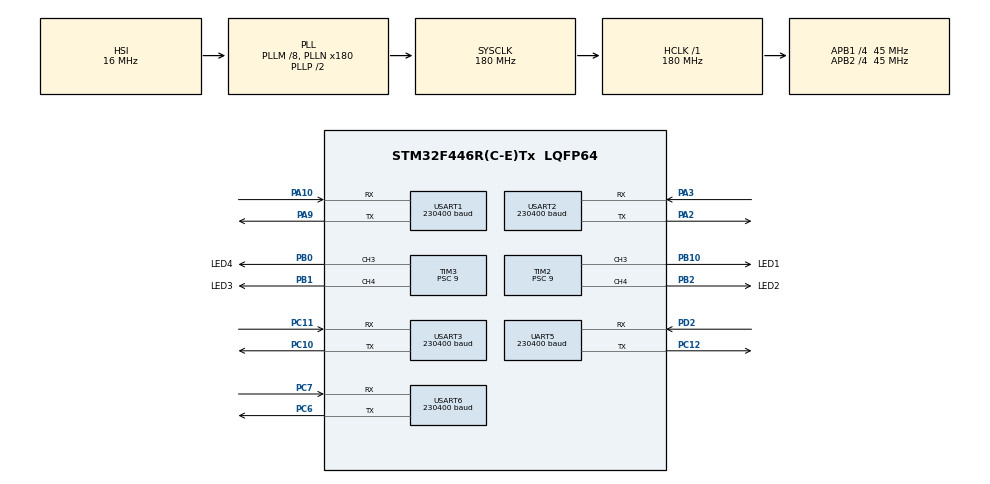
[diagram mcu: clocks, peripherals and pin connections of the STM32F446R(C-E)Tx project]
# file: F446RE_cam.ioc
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Dma.Request0=UART5_RX
Dma.Request1=UART5_TX
Dma.Request2=USART1_RX
Dma.Request3=USART1_TX
Dma.Request4=USART2_RX
Dma.Request5=USART2_TX
Dma.Request6=USART3_RX
Dma.Request7=USART3_TX
Dma.Request8=USART6_RX
Dma.Request9=USART6_TX
Dma.UART5_RX.0.Direction=DMA_PERIPH_TO_MEMORY
Dma.UART5_RX.0.FIFOMode=DMA_FIFOMODE_DISABLE
Dma.UART5_RX.0.Instance=DMA1_Stream0
Dma.UART5_RX.0.MemDataAlignment=DMA_MDATAALIGN_BYTE
Dma.UART5_RX.0.MemInc=DMA_MINC_ENABLE
Dma.UART5_RX.0.Mode=DMA_CIRCULAR
Dma.UART5_RX.0.PeriphDataAlignment=DMA_PDATAALIGN_BYTE
Dma.UART5_RX.0.PeriphInc=DMA_PINC_DISABLE
Dma.UART5_RX.0.Priority=DMA_PRIORITY_LOW
Dma.UART5_TX.1.Direction=DMA_MEMORY_TO_PERIPH
Dma.UART5_TX.1.FIFOMode=DMA_FIFOMODE_DISABLE
Dma.UART5_TX.1.Instance=DMA1_Stream7
Dma.UART5_TX.1.MemDataAlignment=DMA_MDATAALIGN_BYTE
Dma.UART5_TX.1.MemInc=DMA_MINC_ENABLE
Dma.UART5_TX.1.Mode=DMA_CIRCULAR
Dma.UART5_TX.1.PeriphDataAlignment=DMA_PDATAALIGN_BYTE
Dma.UART5_TX.1.PeriphInc=DMA_PINC_DISABLE
Dma.UART5_TX.1.Priority=DMA_PRIORITY_LOW
Dma.USART1_RX.2.Direction=DMA_PERIPH_TO_MEMORY
Dma.USART1_RX.2.FIFOMode=DMA_FIFOMODE_DISABLE
Dma.USART1_RX.2.Instance=DMA2_Stream2
Dma.USART1_RX.2.MemDataAlignment=DMA_MDATAALIGN_BYTE
Dma.USART1_RX.2.MemInc=DMA_MINC_ENABLE
Dma.USART1_RX.2.Mode=DMA_CIRCULAR
Dma.USART1_RX.2.PeriphDataAlignment=DMA_PDATAALIGN_BYTE
Dma.USART1_RX.2.PeriphInc=DMA_PINC_DISABLE
Dma.USART1_RX.2.Priority=DMA_PRIORITY_LOW
Dma.USART1_TX.3.Direction=DMA_MEMORY_TO_PERIPH
Dma.USART1_TX.3.FIFOMode=DMA_FIFOMODE_DISABLE
Dma.USART1_TX.3.Instance=DMA2_Stream7
Dma.USART1_TX.3.MemDataAlignment=DMA_MDATAALIGN_BYTE
Dma.USART1_TX.3.MemInc=DMA_MINC_ENABLE
Dma.USART1_TX.3.Mode=DMA_CIRCULAR
Dma.USART1_TX.3.PeriphDataAlignment=DMA_PDATAALIGN_BYTE
Dma.USART1_TX.3.PeriphInc=DMA_PINC_DISABLE
Dma.USART1_TX.3.Priority=DMA_PRIORITY_LOW
Dma.USART2_RX.4.Direction=DMA_PERIPH_TO_MEMORY
Dma.USART2_RX.4.FIFOMode=DMA_FIFOMODE_DISABLE
Dma.USART2_RX.4.Instance=DMA1_Stream5
Dma.USART2_RX.4.MemDataAlignment=DMA_MDATAALIGN_BYTE
Dma.USART2_RX.4.MemInc=DMA_MINC_ENABLE
Dma.USART2_RX.4.Mode=DMA_CIRCULAR
Dma.USART2_RX.4.PeriphDataAlignment=DMA_PDATAALIGN_BYTE
Dma.USART2_RX.4.PeriphInc=DMA_PINC_DISABLE
Dma.USART2_RX.4.Priority=DMA_PRIORITY_LOW
Dma.USART2_TX.5.Direction=DMA_MEMORY_TO_PERIPH
Dma.USART2_TX.5.FIFOMode=DMA_FIFOMODE_DISABLE
Dma.USART2_TX.5.Instance=DMA1_Stream6
Dma.USART2_TX.5.MemDataAlignment=DMA_MDATAALIGN_BYTE
Dma.USART2_TX.5.MemInc=DMA_MINC_ENABLE
Dma.USART2_TX.5.Mode=DMA_CIRCULAR
Dma.USART2_TX.5.PeriphDataAlignment=DMA_PDATAALIGN_BYTE
Dma.USART2_TX.5.PeriphInc=DMA_PINC_DISABLE
Dma.USART2_TX.5.Priority=DMA_PRIORITY_LOW
Dma.USART3_RX.6.Direction=DMA_PERIPH_TO_MEMORY
Dma.USART3_RX.6.FIFOMode=DMA_FIFOMODE_DISABLE
Dma.USART3_RX.6.Instance=DMA1_Stream1
Dma.USART3_RX.6.MemDataAlignment=DMA_MDATAALIGN_BYTE
Dma.USART3_RX.6.MemInc=DMA_MINC_ENABLE
Dma.USART3_RX.6.Mode=DMA_CIRCULAR
Dma.USART3_RX.6.PeriphDataAlignment=DMA_PDATAALIGN_BYTE
Dma.USART3_RX.6.PeriphInc=DMA_PINC_DISABLE
Dma.USART3_RX.6.Priority=DMA_PRIORITY_LOW
Dma.USART3_TX.7.Direction=DMA_MEMORY_TO_PERIPH
Dma.USART3_TX.7.FIFOMode=DMA_FIFOMODE_DISABLE
Dma.USART3_TX.7.Instance=DMA1_Stream3
Dma.USART3_TX.7.MemDataAlignment=DMA_MDATAALIGN_BYTE
Dma.USART3_TX.7.MemInc=DMA_MINC_ENABLE
Dma.USART3_TX.7.Mode=DMA_CIRCULAR
Dma.USART3_TX.7.PeriphDataAlignment=DMA_PDATAALIGN_BYTE
Dma.USART3_TX.7.PeriphInc=DMA_PINC_DISABLE
Dma.USART3_TX.7.Priority=DMA_PRIORITY_LOW
Dma.USART6_RX.8.Direction=DMA_PERIPH_TO_MEMORY
Dma.USART6_RX.8.FIFOMode=DMA_FIFOMODE_DISABLE
Dma.USART6_RX.8.Instance=DMA2_Stream1
Dma.USART6_RX.8.MemDataAlignment=DMA_MDATAALIGN_BYTE
Dma.USART6_RX.8.MemInc=DMA_MINC_ENABLE
Dma.USART6_RX.8.Mode=DMA_CIRCULAR
Dma.USART6_RX.8.PeriphDataAlignment=DMA_PDATAALIGN_BYTE
Dma.USART6_RX.8.PeriphInc=DMA_PINC_DISABLE
Dma.USART6_RX.8.Priority=DMA_PRIORITY_LOW
Dma.USART6_TX.9.Direction=DMA_MEMORY_TO_PERIPH
Dma.USART6_TX.9.FIFOMode=DMA_FIFOMODE_DISABLE
Dma.USART6_TX.9.Instance=DMA2_Stream6
Dma.USART6_TX.9.MemDataAlignment=DMA_MDATAALIGN_BYTE
Dma.USART6_TX.9.MemInc=DMA_MINC_ENABLE
Dma.USART6_TX.9.Mode=DMA_CIRCULAR
Dma.USART6_TX.9.PeriphDataAlignment=DMA_PDATAALIGN_BYTE
Dma.USART6_TX.9.PeriphInc=DMA_PINC_DISABLE
Dma.USART6_TX.9.Priority=DMA_PRIORITY_LOW
Mcu.Family=STM32F4
Mcu.Name=STM32F446R(C-E)Tx
Mcu.Package=LQFP64
NVIC.DMA1_Stream0_IRQn=true\:0\:0\:false\:false\:true\:false\:true\:true
NVIC.DMA1_Stream1_IRQn=true\:0\:0\:false\:false\:true\:false\:true\:true
NVIC.DMA1_Stream3_IRQn=true\:0\:0\:false\:false\:true\:false\:true\:true
NVIC.DMA1_Stream5_IRQn=true\:0\:0\:false\:false\:true\:false\:true\:true
NVIC.DMA1_Stream6_IRQn=true\:0\:0\:false\:false\:true\:false\:true\:true
NVIC.DMA1_Stream7_IRQn=true\:0\:0\:false\:false\:true\:false\:true\:true
NVIC.DMA2_Stream1_IRQn=true\:0\:0\:false\:false\:true\:false\:true\:true
NVIC.DMA2_Stream2_IRQn=true\:0\:0\:false\:false\:true\:false\:true\:true
NVIC.DMA2_Stream6_IRQn=true\:0\:0\:false\:false\:true\:false\:true\:true
NVIC.DMA2_Stream7_IRQn=true\:0\:0\:false\:false\:true\:false\:true\:true
NVIC.PriorityGroup=NVIC_PRIORITYGROUP_4
NVIC.UART5_IRQn=true\:0\:0\:false\:false\:true\:true\:true\:true
NVIC.USART1_IRQn=true\:0\:0\:false\:false\:true\:false\:true\:true
NVIC.USART2_IRQn=true\:0\:0\:false\:false\:true\:false\:true\:true
NVIC.USART3_IRQn=true\:0\:0\:false\:false\:true\:false\:true\:true
NVIC.USART6_IRQn=true\:0\:0\:false\:false\:true\:false\:true\:true
PA10.Mode=Asynchronous
PA10.Signal=USART1_RX
PA2.Mode=Asynchronous
PA2.Signal=USART2_TX
PA3.Mode=Asynchronous
PA3.Signal=USART2_RX
PA9.Mode=Asynchronous
PA9.Signal=USART1_TX
PB0.GPIO_Label=LED4
PB0.Signal=S_TIM3_CH3
PB1.GPIO_Label=LED3
PB1.Signal=S_TIM3_CH4
PB10.GPIO_Label=LED1
PB10.Signal=S_TIM2_CH3
PB2.GPIO_Label=LED2
PB2.Signal=S_TIM2_CH4
PC10.Mode=Asynchronous
PC10.Signal=USART3_TX
PC11.Mode=Asynchronous
PC11.Signal=USART3_RX
PC12.Mode=Asynchronous
PC12.Signal=UART5_TX
PC6.Mode=Asynchronous
PC6.Signal=USART6_TX
PC7.Mode=Asynchronous
PC7.Signal=USART6_RX
PD2.Mode=Asynchronous
PD2.Signal=UART5_RX
ProjectManager.HeapSize=0x200
ProjectManager.StackSize=0x400
ProjectManager.TargetToolchain=Makefile
RCC.AHBFreq_Value=180000000
RCC.APB1CLKDivider=RCC_HCLK_DIV4
RCC.APB1Freq_Value=45000000
RCC.APB1TimFreq_Value=90000000
RCC.APB2CLKDivider=RCC_HCLK_DIV4
RCC.APB2Freq_Value=45000000
RCC.APB2TimFreq_Value=90000000
RCC.CortexFreq_Value=180000000
RCC.HCLKFreq_Value=180000000
RCC.PLLM=8
RCC.PLLN=180
RCC.SYSCLKFreq_VALUE=180000000
RCC.SYSCLKSource=RCC_SYSCLKSOURCE_PLLCLK
RCC.USBFreq_Value=180000000
RCC.VCOOutputFreq_Value=360000000
SH.S_TIM2_CH3.0=TIM2_CH3,PWM Generation3 CH3
SH.S_TIM2_CH4.0=TIM2_CH4,PWM Generation4 CH4
SH.S_TIM3_CH3.0=TIM3_CH3,PWM Generation3 CH3
SH.S_TIM3_CH4.0=TIM3_CH4,PWM Generation4 CH4
TIM2.Channel-PWM\ Generation3\ CH3=TIM_CHANNEL_3
TIM2.Channel-PWM\ Generation4\ CH4=TIM_CHANNEL_4
TIM2.Period=7999
TIM2.Prescaler=9
TIM3.Channel-PWM\ Generation3\ CH3=TIM_CHANNEL_3
TIM3.Channel-PWM\ Generation4\ CH4=TIM_CHANNEL_4
TIM3.Period=7999
TIM3.Prescaler=9
UART5.BaudRate=230400
UART5.VirtualMode=Asynchronous
USART1.BaudRate=230400
USART1.VirtualMode=VM_ASYNC
USART2.BaudRate=230400
USART2.VirtualMode=VM_ASYNC
USART3.BaudRate=230400
USART3.VirtualMode=VM_ASYNC
USART6.BaudRate=230400
USART6.VirtualMode=VM_ASYNC
board=custom

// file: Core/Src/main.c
/* USER CODE BEGIN Header */
/**
 ******************************************************************************
 * @file           : main.c
 * @brief          : Main program body
 ******************************************************************************
 * @attention
 *
 * Copyright (c) 2025 STMicroelectronics.
 * All rights reserved.
 *
 * This software is licensed under terms that can be found in the LICENSE file
 * in the root directory of this software component.
 * If no LICENSE file comes with this software, it is provided AS-IS.
 *
 ******************************************************************************
 */
/* USER CODE END Header */
#include "main.h"

#include "dma.h"
#include "gpio.h"
#include "tim.h"
#include "usart.h"

void SystemClock_Config(void);

int main(void) {

      /* MCU Configuration--------------------------------------------------------*/

      /* Reset of all peripherals, Initializes the Flash interface and the Systick. */
      HAL_Init();

      /* Configure the system clock */
      SystemClock_Config();

      /* Initialize all configured peripherals */
      MX_GPIO_Init();
      MX_DMA_Init();
      MX_TIM2_Init();
      MX_TIM3_Init();
      MX_UART5_Init();
      MX_USART1_UART_Init();
      MX_USART2_UART_Init();
      MX_USART3_UART_Init();
      MX_USART6_UART_Init();
      /* USER CODE BEGIN 2 */
      setup();

      /* USER CODE END 2 */

      /* Infinite loop */
      /* USER CODE BEGIN WHILE */
      main_app();
      while (1) {
            /* USER CODE END WHILE */

      }
}

void SystemClock_Config(void) {
      RCC_OscInitTypeDef RCC_OscInitStruct = {0};
      RCC_ClkInitTypeDef RCC_ClkInitStruct = {0};

      /** Configure the main internal regulator output voltage
       */
      __HAL_RCC_PWR_CLK_ENABLE();
      __HAL_PWR_VOLTAGESCALING_CONFIG(PWR_REGULATOR_VOLTAGE_SCALE1);

      /** Initializes the RCC Oscillators according to the specified parameters
       * in the RCC_OscInitTypeDef structure.
       */
      RCC_OscInitStruct.OscillatorType = RCC_OSCILLATORTYPE_HSI;
      RCC_OscInitStruct.HSIState = RCC_HSI_ON;
      RCC_OscInitStruct.HSICalibrationValue = RCC_HSICALIBRATION_DEFAULT;
      RCC_OscInitStruct.PLL.PLLState = RCC_PLL_ON;
      RCC_OscInitStruct.PLL.PLLSource = RCC_PLLSOURCE_HSI;
      RCC_OscInitStruct.PLL.PLLM = 8;
      RCC_OscInitStruct.PLL.PLLN = 180;
      RCC_OscInitStruct.PLL.PLLP = RCC_PLLP_DIV2;
      RCC_OscInitStruct.PLL.PLLQ = 2;
      RCC_OscInitStruct.PLL.PLLR = 2;
      if (HAL_RCC_OscConfig(&RCC_OscInitStruct) != HAL_OK) {
            Error_Handler();
      }

      /** Activate the Over-Drive mode
       */
      if (HAL_PWREx_EnableOverDrive() != HAL_OK) {
            Error_Handler();
      }

      /** Initializes the CPU, AHB and APB buses clocks
       */
      RCC_ClkInitStruct.ClockType = RCC_CLOCKTYPE_HCLK | RCC_CLOCKTYPE_SYSCLK | RCC_CLOCKTYPE_PCLK1 | RCC_CLOCKTYPE_PCLK2;
      RCC_ClkInitStruct.SYSCLKSource = RCC_SYSCLKSOURCE_PLLCLK;
      RCC_ClkInitStruct.AHBCLKDivider = RCC_SYSCLK_DIV1;
      RCC_ClkInitStruct.APB1CLKDivider = RCC_HCLK_DIV4;
      RCC_ClkInitStruct.APB2CLKDivider = RCC_HCLK_DIV4;

      if (HAL_RCC_ClockConfig(&RCC_ClkInitStruct, FLASH_LATENCY_5) != HAL_OK) {
            Error_Handler();
      }
}

void Error_Handler(void) {
      __disable_irq();
      while (1) {
      }
}
